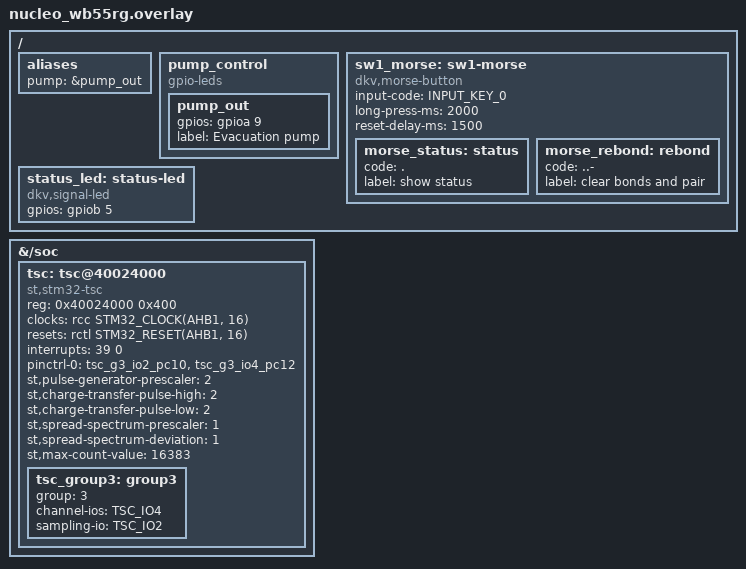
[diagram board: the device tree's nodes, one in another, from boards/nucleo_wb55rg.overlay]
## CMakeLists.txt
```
cmake_minimum_required(VERSION 3.20.0)

# Board-specific overlay/conf are auto-picked from boards/<board>.{overlay,conf}
set(BOARD_ROOT ${CMAKE_CURRENT_LIST_DIR})

# Default target board. Override on the command line with:
#   west build -b <board> .
if(NOT DEFINED BOARD)
  set(BOARD "nucleo_wb55rg")
endif()

# Use OpenOCD as the default flash/debug runner (the board otherwise defaults to
# stm32cubeprogrammer). `west flash` / `west debug` now use OpenOCD with no -r.
if(NOT DEFINED BOARD_FLASH_RUNNER)
  set(BOARD_FLASH_RUNNER openocd)
endif()
if(NOT DEFINED BOARD_DEBUG_RUNNER)
  set(BOARD_DEBUG_RUNNER openocd)
endif()

# Out-of-tree drivers (morse-button, signal-led) live in a Zephyr module.
list(APPEND ZEPHYR_EXTRA_MODULES ${CMAKE_CURRENT_LIST_DIR}/drivers)

find_package(Zephyr REQUIRED HINTS $ENV{ZEPHYR_BASE})
project(bucket C)

target_sources(app PRIVATE
  src/main.c
  src/pump.c
  src/level.c
  src/tsc.c
  src/gatt.c
  src/bond.c
  src/ui.c
)
```

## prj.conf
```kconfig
# ---- bucket firmware base config ----

CONFIG_MAIN_STACK_SIZE=2048

# Logging over the USB VCP / RTT. Cheap during bring-up; trim later for power.
CONFIG_LOG=y
CONFIG_SERIAL=y
CONFIG_CONSOLE=y
CONFIG_UART_CONSOLE=y

# Interactive shell over the ST-LINK virtual COM port (milestone-1 bring-up).
CONFIG_SHELL=y
CONFIG_SHELL_BACKEND_SERIAL=y
CONFIG_LOG_BACKEND_UART=y
CONFIG_KERNEL_SHELL=y
CONFIG_DEVICE_SHELL=y

# GPIO for the pump driver and status LED.
CONFIG_GPIO=y

# TSC capacitive sensing is exposed through the input subsystem.
# (The STM32 TSC driver is enabled by the devicetree overlay; it selects
#  CONFIG_INPUT automatically, but we ask for it explicitly for clarity.)
CONFIG_INPUT=y

# ---- Bluetooth LE (STM32WB) ----
CONFIG_BT=y
CONFIG_BT_PERIPHERAL=y
CONFIG_BT_DEVICE_NAME="BucketEvac"
CONFIG_BT_DIS=y
CONFIG_BT_DIS_MODEL_NUMBER=y
CONFIG_BT_DIS_MODEL_NUMBER_STR="BucketEvac"
CONFIG_BT_DIS_MANUF_NAME=y
CONFIG_BT_DIS_MANUF_NAME_STR="Denis Kokarev"
# BT shell commands for bring-up experimentation.
CONFIG_BT_SHELL=y

# ---- Pairing / bonding ----
# Secure (encrypted) GATT access with persistent bonds. New pairings are only
# accepted during a bonding window (see src/bond.c), gated via the
# pairing-accept callback.
CONFIG_BT_SMP=y
CONFIG_BT_BONDABLE=y
CONFIG_BT_SMP_APP_PAIRING_ACCEPT=y

# Persist bonds in the `storage` flash partition.
CONFIG_BT_SETTINGS=y
CONFIG_FLASH=y
CONFIG_FLASH_MAP=y
CONFIG_NVS=y
CONFIG_SETTINGS=y
# `settings list|read|write|delete` to inspect/wipe stored bonds (bt/keys/...).
CONFIG_SETTINGS_SHELL=y
CONFIG_SHELL_STACK_SIZE=4096
# e2e cleanup: `flash erase` the storage partition, then `kernel reboot cold`.
CONFIG_FLASH_SHELL=y
CONFIG_REBOOT=y
# `input report` injects SW1 presses (e2e drives the morse codes with it).
CONFIG_INPUT_SHELL=y

# Kernel niceties
CONFIG_PRINTK=y
CONFIG_CBPRINTF_FP_SUPPORT=y

# The BT host's deferred settings store (bonds + CCCs -> NVS) runs on the
# system workqueue; 1 KiB overflowed when a bond with two CCCs was re-paired.
CONFIG_SYSTEM_WORKQUEUE_STACK_SIZE=2048
```

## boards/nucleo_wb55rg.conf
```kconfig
# Board-specific Kconfig fragment for nucleo_wb55rg.
# Auto-merged with prj.conf when BOARD=nucleo_wb55rg.

# The WB55 BLE stack runs on the Cortex-M0+ radio coprocessor; the HCI link to
# it is provided by the IPM/IPC transport. Keep BT managed here so a non-BLE
# board build (e.g. for host tests) stays clean.
CONFIG_BT=y
```

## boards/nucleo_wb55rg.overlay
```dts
/*
 * nucleo_wb55rg overlay for the bucket project.
 *
 * Two jobs:
 *   1. Instantiate the STM32WB55 TSC peripheral. Unlike the F0/U0 SoCs, the
 *      WB `.dtsi` does NOT ship a `tsc` node, so we add it here. Register
 *      address / IRQ / clock / reset come from the STM32WB55 reference manual
 *      and CMSIS headers:
 *        TSC @ 0x40024000, IRQ 39, RCC AHB1 bit 16 (TSCEN/TSCRST).
 *   2. Declare the `pump` GPIO output.
 *   3. Board UI: SW1 as a morse button (codes below) and LED1 (blue, PB5)
 *      as the signal LED. PB5 has no timer PWM output on the WB55, so the
 *      signal-led driver uses software PWM on the GPIO.
 *
 * TSC pin choice: Group 3, on the ARDUINO headers (UM2819 Table 9), with no
 * other board function on either pin:
 *   - PC10 = G3_IO2 = D4 (CN9-5) -> sampling capacitor (external Cs to GND)
 *   - PC12 = G3_IO4 = D8 (CN5-1) -> sensing electrode (via series Rs)
 * G3_IO1 (PA15/D5) is avoided: the board DTS binds it to pwm2. Group 1
 * (PB12-15) is morpho-only and PB12 is the board's LPUART1 RTS.
 * Keep sampling-io and channel-ios in the same group.
 */

#include <zephyr/dt-bindings/input/input-event-codes.h>
#include <zephyr/dt-bindings/input/stm32-tsc-defines.h>

/ {
	aliases {
		pump = &pump_out;
	};

	/* Simple GPIO output for the pump driver transistor (base resistor):
	 * PA9 = ARDUINO D9 (CN5-2), high = pump ON. D10-D13 (PA4-PA7) are
	 * avoided: the board DTS gives them to spi1 (PA6 also LPUART1 CTS). */
	pump_control {
		compatible = "gpio-leds";
		pump_out: pump_out {
			gpios = <&gpioa 9 GPIO_ACTIVE_HIGH>;
			label = "Evacuation pump";
		};
	};

	/* SW1 (gpio-keys INPUT_KEY_0) decoded as morse codes. No `input`
	 * phandle: listen to any device so `input report` can inject presses
	 * from the shell (e2e). */
	sw1_morse: sw1-morse {
		compatible = "dkv,morse-button";
		input-code = <INPUT_KEY_0>;
		long-press-ms = <2000>;
		reset-delay-ms = <1500>;

		morse_status: status {
			code = ".";
			label = "show status";
		};
		morse_rebond: rebond {
			code = "..-";
			label = "clear bonds and pair";
		};
	};

	status_led: status-led {
		compatible = "dkv,signal-led";
		gpios = <&gpiob 5 GPIO_ACTIVE_HIGH>;
	};
};

/* The WB `soc` node is unlabeled; extend it by path to add the TSC. */
&{/soc} {
	tsc: tsc@40024000 {
		compatible = "st,stm32-tsc";
		reg = <0x40024000 0x400>;
		clocks = <&rcc STM32_CLOCK(AHB1, 16)>;
		resets = <&rctl STM32_RESET(AHB1, 16)>;
		interrupts = <39 0>;
		interrupt-names = "global";

		pinctrl-0 = <&tsc_g3_io2_pc10 &tsc_g3_io4_pc12>;
		pinctrl-names = "default";

		st,pulse-generator-prescaler = <2>;
		st,charge-transfer-pulse-high = <2>;
		st,charge-transfer-pulse-low = <2>;
		st,spread-spectrum-prescaler = <1>;
		st,spread-spectrum-deviation = <1>;
		st,max-count-value = <16383>;

		status = "okay";

		tsc_group3: group3 {
			/* Hardware TSC Group 3. The driver indexes registers as
			 * (group - 1), so Group 3 is `group = <3>`. */
			group = <3>;
			channel-ios = <TSC_IO4>;  /* PC12 / D8 electrode */
			sampling-io = <TSC_IO2>;  /* PC10 / D4 + external Cs */
			/* No `tsc-keys` child: we read the raw acquisition count
			 * ourselves (see src/tsc.c) for level sensing + validation. */
		};
	};
};
```

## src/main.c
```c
/*
 * bucket — dehumidifier bucket auto-evacuator
 *
 * Milestone 1 bring-up: boot the WB55, initialize the TSC capacitive sensor
 * and the Bluetooth controller, and run a shell. The pump control loop is
 * wired in but harmless until a real electrode + pump are connected and the
 * TSC thresholds are characterized.
 */
#include "adv.h"
#include "bond.h"
#include "gatt.h"
#include "level.h"
#include "pump.h"
#include "ui.h"

#include <zephyr/bluetooth/bluetooth.h>
#include <zephyr/bluetooth/conn.h>
#include <zephyr/bluetooth/uuid.h>
#include <zephyr/kernel.h>
#include <zephyr/logging/log.h>
#include <zephyr/settings/settings.h>

LOG_MODULE_REGISTER(main, LOG_LEVEL_INF);

#define CONTROL_PERIOD_MS 200

/* Service UUID in the primary advertisement so centrals can filter/scan for us;
 * must match gatt.c / client ble.ts. Name + bonding marker go in the scan
 * response (name + UUID together would overflow a single 31-byte packet). */
static const struct bt_data ad[] = {
	BT_DATA_BYTES(BT_DATA_FLAGS, (BT_LE_AD_GENERAL | BT_LE_AD_NO_BREDR)),
	BT_DATA_BYTES(BT_DATA_UUID128_ALL,
		      BT_UUID_128_ENCODE(0xd2f2a658, 0x2605, 0x4993, 0x9794, 0x01961b93a091)),
};

/* Manufacturer data: company 0xFFFF (test/internal) + a bonding-mode flag byte.
 * mfg_data[2] == 1 while the bonding window is open (see bt_set_bonding_adv). */
static uint8_t mfg_data[] = {0xFF, 0xFF, 0x00};

static const struct bt_data sd[] = {
	BT_DATA(BT_DATA_NAME_COMPLETE, CONFIG_BT_DEVICE_NAME, sizeof(CONFIG_BT_DEVICE_NAME) - 1),
	BT_DATA(BT_DATA_MANUFACTURER_DATA, mfg_data, sizeof(mfg_data)),
};

void bt_set_bonding_adv(bool on)
{
	mfg_data[2] = on ? 1 : 0;
	/* Live-update if currently advertising; the byte is also authoritative for
	 * the next start_adv(), so ignore errors (e.g. while connected). */
	(void)bt_le_adv_update_data(ad, ARRAY_SIZE(ad), sd, ARRAY_SIZE(sd));
}

static int start_adv(void)
{
	int err = bt_le_adv_start(BT_LE_ADV_CONN_FAST_1, ad, ARRAY_SIZE(ad), sd, ARRAY_SIZE(sd));
	if (err == 0) {
		LOG_INF("advertising as \"%s\"", CONFIG_BT_DEVICE_NAME);
	}
	return err;
}

/*
 * Re-advertising is deferred to the system workqueue: restarting from inside
 * the disconnected callback fails with -ENOMEM on the WB controller because the
 * connection object isn't freed yet. Retry until a slot is available.
 */
static void adv_work_handler(struct k_work *work)
{
	int err = start_adv();
	if (err == -ENOMEM || err == -EAGAIN) {
		k_work_reschedule(k_work_delayable_from_work(work), K_MSEC(100));
	} else if (err) {
		LOG_ERR("advertising start failed (%d)", err);
	}
}

static K_WORK_DELAYABLE_DEFINE(adv_work, adv_work_handler);

static void on_connected(struct bt_conn *conn, uint8_t err)
{
	char addr[BT_ADDR_LE_STR_LEN];

	if (err) {
		LOG_ERR("connection failed (0x%02x)", err);
		return;
	}
	bt_addr_le_to_str(bt_conn_get_dst(conn), addr, sizeof(addr));
	LOG_INF("central connected: %s (sec L%d)", addr, bt_conn_get_security(conn));
}

static void on_disconnected(struct bt_conn *conn, uint8_t reason)
{
	/* Connectable advertising stops on connect; restart it (deferred) so the
	 * board is discoverable again after the central goes away. */
	LOG_INF("central disconnected (reason 0x%02x), re-advertising", reason);
	k_work_reschedule(&adv_work, K_MSEC(50));
}

static void on_security_changed(struct bt_conn *conn, bt_security_t level,
				enum bt_security_err err)
{
	char addr[BT_ADDR_LE_STR_LEN];

	bt_addr_le_to_str(bt_conn_get_dst(conn), addr, sizeof(addr));
	if (err) {
		LOG_WRN("security change failed: %s L%d err %d", addr, level, err);
	} else {
		LOG_INF("security changed: %s L%d", addr, level);
	}
}

BT_CONN_CB_DEFINE(conn_cbs) = {
	.connected = on_connected,
	.disconnected = on_disconnected,
	.security_changed = on_security_changed,
};

static void bt_bringup(void)
{
	int err = bt_enable(NULL);
	if (err) {
		LOG_ERR("bt_enable failed (%d) — is the WB55 wireless coprocessor "
			"stack flashed on the M0+?",
			err);
		return;
	}
	LOG_INF("Bluetooth controller ready");

	if (IS_ENABLED(CONFIG_SETTINGS)) {
		settings_load(); /* restore stored bonds */
	}
	if (bond_init(ui_on_bond_event) != 0) {
		LOG_ERR("bond init failed");
	}
	if (ui_init() != 0) {
		LOG_ERR("ui init failed");
	}
	ui_show_status();

	if (start_adv() != 0) {
		k_work_reschedule(&adv_work, K_MSEC(100));
	}
}

int main(void)
{
	LOG_INF("bucket starting on %s", CONFIG_BOARD);

	if (pump_init() != 0) {
		LOG_ERR("pump init failed");
	}
	if (level_init() != 0) {
		LOG_ERR("level init failed");
	}

	bt_bringup();

	LOG_INF("bring-up complete: TSC + BT + shell running");

	/* Control loop: in AUTO follow the level sensor; FORCE_ON/OFF come from
	 * the BLE pump characteristic. The min-run / max-run guards are enforced
	 * inside the pump module. Status is pushed to subscribed centrals. */
	while (1) {
		switch (pump_get_mode()) {
		case PUMP_MODE_FORCE_ON:
			pump_request(true);
			break;
		case PUMP_MODE_FORCE_OFF:
			pump_request(false);
			break;
		case PUMP_MODE_AUTO:
		default:
			pump_request(level_water_present());
			break;
		}
		pump_tick();
		bucket_gatt_notify();
		k_sleep(K_MSEC(CONTROL_PERIOD_MS));
	}

	return 0;
}
```

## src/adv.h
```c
/*
 * Advertising control shared between main.c (owns the advertiser) and bond.c
 * (opens/closes the bonding window).
 */
#ifndef BUCKET_ADV_H
#define BUCKET_ADV_H

#include <stdbool.h>

/*
 * Toggle the "bonding mode" marker in the advertising data. The mobile client
 * only auto-pairs when it sees this marker, so pairing is effectively initiated
 * by the user opening the window (SW1 / `bond`), not by mere discovery.
 */
void bt_set_bonding_adv(bool on);

#endif /* BUCKET_ADV_H */
```

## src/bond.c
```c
#include "bond.h"
#include "adv.h"

#include <string.h>
#include <zephyr/bluetooth/bluetooth.h>
#include <zephyr/bluetooth/conn.h>
#include <zephyr/kernel.h>
#include <zephyr/logging/log.h>
#include <zephyr/shell/shell.h>
#include <zephyr/sys/atomic.h>

LOG_MODULE_REGISTER(bond, LOG_LEVEL_INF);

#define BOND_WINDOW_SECONDS 60

static atomic_t window_open; /* 1 while new pairings are accepted */
static bond_event_cb_t event_cb;

static void notify(enum bond_event ev)
{
	if (event_cb) {
		event_cb(ev);
	}
}

/* Close the window if it is open; true if this call closed it. Callers race
 * (timeout vs. pairing result), so exactly one of them reports. */
static bool close_window(void)
{
	if (!atomic_cas(&window_open, 1, 0)) {
		return false;
	}
	bt_set_bonding_adv(false);
	return true;
}

/* Runs in the system workqueue (thread context) so BT APIs are safe. */
static void window_timeout(struct k_work *work)
{
	ARG_UNUSED(work);
	if (close_window()) {
		LOG_INF("bonding window closed (timeout)");
		notify(BOND_EV_WINDOW_TIMEOUT);
	}
}

static K_WORK_DELAYABLE_DEFINE(window_work, window_timeout);

static void count_bond(const struct bt_bond_info *info, void *user_data)
{
	ARG_UNUSED(info);
	(*(int *)user_data)++;
}

bool bond_exists(void)
{
	int n = 0;

	bt_foreach_bond(BT_ID_DEFAULT, count_bond, &n);
	return n > 0;
}

bool bond_window_is_open(void)
{
	return atomic_get(&window_open) != 0;
}

void bond_rebond(void)
{
	/* Clear first so the board always re-pairs from scratch: a phone that
	 * dropped its keys (OS-side unpair) can pair again, and the window only
	 * ever ends with exactly the newly paired phone bonded. Connected peers
	 * are disconnected by bt_unpair(). */
	int err = bt_unpair(BT_ID_DEFAULT, NULL);

	LOG_INF("cleared all bonds (%d)", err);
	atomic_set(&window_open, 1);
	bt_set_bonding_adv(true); /* advertise the marker so the app auto-pairs */
	k_work_reschedule(&window_work, K_SECONDS(BOND_WINDOW_SECONDS));
	LOG_INF("bonding mode: accepting a new pairing for %d s "
		"(read the secure Pump attribute from the client)",
		BOND_WINDOW_SECONDS);
	notify(BOND_EV_WINDOW_OPEN);
}

/* ---- pairing callbacks ---- */

#if defined(CONFIG_BT_SMP_APP_PAIRING_ACCEPT)
static enum bt_security_err pairing_accept(struct bt_conn *conn,
					   const struct bt_conn_pairing_feat *const feat)
{
	ARG_UNUSED(conn);
	ARG_UNUSED(feat);

	if (atomic_get(&window_open)) {
		LOG_INF("pairing request accepted");
		return BT_SECURITY_ERR_SUCCESS;
	}

	LOG_WRN("pairing rejected: not in bonding mode (SW1 short-short-long or `bond`)");
	return BT_SECURITY_ERR_PAIR_NOT_ALLOWED;
}
#endif

static const struct bt_conn_auth_cb auth_cb = {
#if defined(CONFIG_BT_SMP_APP_PAIRING_ACCEPT)
	.pairing_accept = pairing_accept,
#endif
};

static void pairing_complete(struct bt_conn *conn, bool bonded)
{
	char addr[BT_ADDR_LE_STR_LEN];

	bt_addr_le_to_str(bt_conn_get_dst(conn), addr, sizeof(addr));
	LOG_INF("pairing complete: %s (bonded=%d)", addr, bonded);
	/* One successful bond per window. */
	if (close_window()) {
		k_work_cancel_delayable(&window_work);
		notify(BOND_EV_PAIRED);
	}
}

static void pairing_failed(struct bt_conn *conn, enum bt_security_err reason)
{
	ARG_UNUSED(conn);
	LOG_WRN("pairing failed (reason %d)", reason);
	/* Only a failure inside the window is the user's pairing attempt; outside
	 * it, it's a rejected stranger and must not change the UI. */
	if (close_window()) {
		k_work_cancel_delayable(&window_work);
		notify(BOND_EV_FAILED);
	}
}

static struct bt_conn_auth_info_cb auth_info_cb = {
	.pairing_complete = pairing_complete,
	.pairing_failed = pairing_failed,
};

int bond_init(bond_event_cb_t cb)
{
	int err;

	event_cb = cb;
	err = bt_conn_auth_cb_register(&auth_cb);
	if (err) {
		return err;
	}
	return bt_conn_auth_info_cb_register(&auth_info_cb);
}

/* ---- shell ---- */

static int cmd_bond(const struct shell *sh, size_t argc, char **argv)
{
	if (argc > 1 && strcmp(argv[1], "clear") == 0) {
		int err = bt_unpair(BT_ID_DEFAULT, NULL); /* remove all bonds (recovery) */
		shell_print(sh, "cleared all bonds (%d)", err);
		return 0;
	}
	bond_rebond();
	shell_print(sh, "bonding mode ON for %d s — read the secure Pump attribute to pair",
		    BOND_WINDOW_SECONDS);
	return 0;
}

SHELL_CMD_REGISTER(bond, NULL,
		   "Clear bonds and open the bonding window for 60s (same as SW1 "
		   "short-short-long); `bond clear` only drops all bonds",
		   cmd_bond);
```

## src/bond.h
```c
/*
 * BLE bonding control.
 *
 * New pairings are only accepted during a short "bonding window". It is opened
 * by bond_rebond() (SW1 code short-short-long, or the `bond` shell command),
 * which first clears all existing bonds, so the board is always re-paired from
 * scratch. A client pairs during that window by reading the secure Pump
 * characteristic. Already-bonded centrals reconnect with their stored keys at
 * any time, without the window.
 */
#ifndef BUCKET_BOND_H
#define BUCKET_BOND_H

#include <stdbool.h>

enum bond_event {
	BOND_EV_WINDOW_OPEN,    /* bonds cleared, accepting a new pairing */
	BOND_EV_PAIRED,         /* a new bond was stored; window closed */
	BOND_EV_WINDOW_TIMEOUT, /* window expired without a pairing */
	BOND_EV_FAILED,         /* pairing failed during the window; window closed */
};

typedef void (*bond_event_cb_t)(enum bond_event ev);

/* Register pairing callbacks; @p cb (may be NULL) gets bond events. Call after
 * bt_enable() and settings_load(). Returns 0 on success. */
int bond_init(bond_event_cb_t cb);

/* Clear all bonds, then open the bonding window for BOND_WINDOW_SECONDS. */
void bond_rebond(void);

bool bond_exists(void);
bool bond_window_is_open(void);

#endif /* BUCKET_BOND_H */
```

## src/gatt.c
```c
#include "gatt.h"
#include "level.h"
#include "pump.h"
#include "tsc.h"

#include <zephyr/bluetooth/gatt.h>
#include <zephyr/bluetooth/uuid.h>
#include <zephyr/kernel.h>
#include <zephyr/logging/log.h>
#include <zephyr/sys/byteorder.h>

LOG_MODULE_REGISTER(gatt, LOG_LEVEL_INF);

/* Service + characteristic UUIDs (must match client/src/utils/ble.ts). */
#define BUCKET_SVC_UUID    BT_UUID_128_ENCODE(0xd2f2a658, 0x2605, 0x4993, 0x9794, 0x01961b93a091)
#define BUCKET_LEVEL_UUID  BT_UUID_128_ENCODE(0x3ec2dc2f, 0xcfdf, 0x49e1, 0xb232, 0xda0dc4a88003)
#define BUCKET_PUMP_UUID   BT_UUID_128_ENCODE(0x4feebce2, 0xe1af, 0x4634, 0x915d, 0x9e62b0756af1)
#define BUCKET_THR_UUID    BT_UUID_128_ENCODE(0xabbb42ed, 0xde11, 0x4636, 0xbbfa, 0x09158f1b0177)

static const struct bt_uuid_128 svc_uuid = BT_UUID_INIT_128(BUCKET_SVC_UUID);
static const struct bt_uuid_128 level_uuid = BT_UUID_INIT_128(BUCKET_LEVEL_UUID);
static const struct bt_uuid_128 pump_uuid = BT_UUID_INIT_128(BUCKET_PUMP_UUID);
static const struct bt_uuid_128 thr_uuid = BT_UUID_INIT_128(BUCKET_THR_UUID);

static bool level_notify_enabled;
static bool thr_notify_enabled;

/* Level payload: [water:u8, pump:u8, rawTSC:u16 LE]. */
static void fill_level(uint8_t buf[4])
{
	uint32_t count = tsc_last_count();
	uint16_t raw = count > UINT16_MAX ? UINT16_MAX : (uint16_t)count;

	buf[0] = level_water_present() ? 1 : 0;
	buf[1] = pump_is_on() ? 1 : 0;
	buf[2] = (uint8_t)(raw & 0xff);
	buf[3] = (uint8_t)(raw >> 8);
}

static ssize_t read_level(struct bt_conn *conn, const struct bt_gatt_attr *attr, void *buf,
			  uint16_t len, uint16_t offset)
{
	uint8_t value[4];

	fill_level(value);
	return bt_gatt_attr_read(conn, attr, buf, len, offset, value, sizeof(value));
}

static void level_ccc_changed(const struct bt_gatt_attr *attr, uint16_t value)
{
	level_notify_enabled = (value == BT_GATT_CCC_NOTIFY);
	LOG_INF("level notifications %s", level_notify_enabled ? "enabled" : "disabled");
}

static ssize_t read_pump(struct bt_conn *conn, const struct bt_gatt_attr *attr, void *buf,
			 uint16_t len, uint16_t offset)
{
	uint8_t mode = (uint8_t)pump_get_mode();

	return bt_gatt_attr_read(conn, attr, buf, len, offset, &mode, sizeof(mode));
}

static ssize_t write_pump(struct bt_conn *conn, const struct bt_gatt_attr *attr, const void *buf,
			  uint16_t len, uint16_t offset, uint8_t flags)
{
	if (offset != 0 || len != 1) {
		return BT_GATT_ERR(BT_ATT_ERR_INVALID_ATTRIBUTE_LEN);
	}

	uint8_t v = ((const uint8_t *)buf)[0];
	if (v > PUMP_MODE_FORCE_ON) {
		return BT_GATT_ERR(BT_ATT_ERR_VALUE_NOT_ALLOWED);
	}

	pump_set_mode((enum pump_mode)v);
	return len;
}

/* Thresholds payload: [off:u16 LE, on:u16 LE] (pump OFF above, ON below). */
static void fill_thresholds(uint8_t buf[4])
{
	uint16_t off, on;

	level_get_thresholds(&off, &on);
	sys_put_le16(off, &buf[0]);
	sys_put_le16(on, &buf[2]);
}

static ssize_t read_thr(struct bt_conn *conn, const struct bt_gatt_attr *attr, void *buf,
			uint16_t len, uint16_t offset)
{
	uint8_t value[4];

	fill_thresholds(value);
	return bt_gatt_attr_read(conn, attr, buf, len, offset, value, sizeof(value));
}

static ssize_t write_thr(struct bt_conn *conn, const struct bt_gatt_attr *attr, const void *buf,
			 uint16_t len, uint16_t offset, uint8_t flags)
{
	if (offset != 0 || len != 4) {
		return BT_GATT_ERR(BT_ATT_ERR_INVALID_ATTRIBUTE_LEN);
	}

	const uint8_t *v = buf;

	if (level_set_thresholds(sys_get_le16(&v[0]), sys_get_le16(&v[2])) != 0) {
		return BT_GATT_ERR(BT_ATT_ERR_VALUE_NOT_ALLOWED);
	}
	return len;
}

static void thr_ccc_changed(const struct bt_gatt_attr *attr, uint16_t value)
{
	thr_notify_enabled = (value == BT_GATT_CCC_NOTIFY);
	LOG_INF("threshold notifications %s", thr_notify_enabled ? "enabled" : "disabled");
}

/* clang-format off */
BT_GATT_SERVICE_DEFINE(bucket_svc,
	BT_GATT_PRIMARY_SERVICE(&svc_uuid),
	BT_GATT_CHARACTERISTIC(&level_uuid.uuid,
			       BT_GATT_CHRC_READ | BT_GATT_CHRC_NOTIFY,
			       BT_GATT_PERM_READ,
			       read_level, NULL, NULL),
	BT_GATT_CCC(level_ccc_changed, BT_GATT_PERM_READ | BT_GATT_PERM_WRITE),
	/* Pump is secure: read + write require an encrypted (bonded) link. A
	 * client reads this attribute to trigger pairing during the bonding
	 * window (see src/bond.c). */
	BT_GATT_CHARACTERISTIC(&pump_uuid.uuid,
			       BT_GATT_CHRC_READ | BT_GATT_CHRC_WRITE,
			       BT_GATT_PERM_READ_ENCRYPT | BT_GATT_PERM_WRITE_ENCRYPT,
			       read_pump, write_pump, NULL),
	/* Pump thresholds (persistent settings): encrypted read/write/subscribe. */
	BT_GATT_CHARACTERISTIC(&thr_uuid.uuid,
			       BT_GATT_CHRC_READ | BT_GATT_CHRC_WRITE | BT_GATT_CHRC_NOTIFY,
			       BT_GATT_PERM_READ_ENCRYPT | BT_GATT_PERM_WRITE_ENCRYPT,
			       read_thr, write_thr, NULL),
	BT_GATT_CCC(thr_ccc_changed, BT_GATT_PERM_READ | BT_GATT_PERM_WRITE_ENCRYPT),
);
/* clang-format on */

void bucket_gatt_notify(void)
{
	if (!level_notify_enabled) {
		return;
	}

	uint8_t value[4];

	fill_level(value);
	/* attrs[1] is the Level characteristic value attribute. */
	bt_gatt_notify(NULL, &bucket_svc.attrs[1], value, sizeof(value));
}

void bucket_gatt_thresholds_changed(void)
{
	if (!thr_notify_enabled) {
		return;
	}

	uint8_t value[4];

	fill_thresholds(value);
	/* attrs[6] is the Thresholds characteristic declaration. */
	bt_gatt_notify(NULL, &bucket_svc.attrs[6], value, sizeof(value));
}
```

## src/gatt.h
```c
/*
 * Bucket custom GATT service.
 *
 * Exposes the water-level status (read + notify) and the pump mode
 * (read + write) to a BLE central (the mobile client). UUIDs and payload
 * layouts are the contract shared with client/src/utils/ble.ts.
 */
#ifndef BUCKET_GATT_H
#define BUCKET_GATT_H

/*
 * Push the current level/pump status to any subscribed central.
 * Safe to call periodically; a no-op when nobody is subscribed.
 */
void bucket_gatt_notify(void);

/* Notify subscribed centrals of new pump thresholds (shell or GATT change). */
void bucket_gatt_thresholds_changed(void);

#endif /* BUCKET_GATT_H */
```

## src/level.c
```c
#include "level.h"
#include "tsc.h"

#include <zephyr/kernel.h>
#include <zephyr/logging/log.h>

LOG_MODULE_REGISTER(level, LOG_LEVEL_INF);

/*
 * Water raises the electrode capacitance, which LOWERS the TSC count. So water
 * is "present" when the count falls below LEVEL_TRIGGER_COUNT, and clears when
 * it rises back above LEVEL_RELEASE_COUNT (hysteresis to stop chatter).
 *
 * Calibrated for Cs = 10 nF and ~21 pF of pin/lead parasitic (bench, see
 * hard/tsc-validation.md). Electrode dry (2 pF) ~330, half band (18 pF) ~195,
 * full (34 pF) ~138. Trigger ~= 14 pF of water signal, release ~= 8 pF. If the
 * parasitic grows by more than ~8 pF, dry drops under the release level:
 * re-measure and re-set these (or move to baseline tracking).
 */
#define LEVEL_TRIGGER_COUNT 220
#define LEVEL_RELEASE_COUNT 260

/* Below this, no sampling cap / electrode is connected (the acquisition
 * completes in ~1 cycle) — not a real reading, so don't report "full". */
#define LEVEL_COUNT_MIN_VALID 20

static bool water_present;

int level_init(void)
{
	water_present = false;
	return tsc_init();
}

bool level_water_present(void)
{
	uint32_t count = tsc_last_count();

	if (count < LEVEL_COUNT_MIN_VALID) {
		/* No acquisition yet, or no electrode/sampling cap wired. */
		if (water_present) {
			water_present = false;
			LOG_INF("sensor not ready (count %u) -> dry", count);
		}
		return false;
	}

	if (water_present) {
		if (count > LEVEL_RELEASE_COUNT) {
			water_present = false;
			LOG_INF("water absent (count %u)", count);
		}
	} else {
		if (count < LEVEL_TRIGGER_COUNT) {
			water_present = true;
			LOG_INF("water PRESENT (count %u)", count);
		}
	}

	return water_present;
}
```

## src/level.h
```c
/*
 * Capacitive water-level sensing via the STM32 TSC.
 *
 * Reads the raw TSC acquisition count (see tsc.c) and applies a threshold with
 * hysteresis to expose a debounced "water present" state. Water raises the
 * electrode capacitance, which lowers the count.
 */
#ifndef BUCKET_LEVEL_H
#define BUCKET_LEVEL_H

#include <stdbool.h>
#include <stdint.h>

/* Set up the input-event subscription. Returns 0 on success. */
int level_init(void);

/* True once water has been detected at/above the electrode (trigger level). */
bool level_water_present(void);

/* Pump hysteresis in raw TSC counts: OFF above `off`, ON below `on`. */
void level_get_thresholds(uint16_t *off, uint16_t *on);

/* Validate (off > on), apply, persist and notify. -EINVAL if invalid. */
int level_set_thresholds(uint16_t off, uint16_t on);

#endif /* BUCKET_LEVEL_H */
```

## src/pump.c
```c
#include "pump.h"

#include <zephyr/device.h>
#include <zephyr/drivers/gpio.h>
#include <zephyr/kernel.h>
#include <zephyr/logging/log.h>

LOG_MODULE_REGISTER(pump, LOG_LEVEL_INF);

/* Minimum time the pump stays on once started, and minimum off time. */
#define PUMP_MIN_RUN_MS 3000
#define PUMP_MIN_OFF_MS 1000

/* Hard safety cap: never run the pump longer than this in one shot. */
#define PUMP_MAX_RUN_MS 120000

/* `pump` is a GPIO alias in boards/<board>.overlay. */
#define PUMP_NODE DT_ALIAS(pump)

#if DT_NODE_HAS_STATUS(PUMP_NODE, okay)
static const struct gpio_dt_spec pump_gpio = GPIO_DT_SPEC_GET(PUMP_NODE, gpios);
#define PUMP_HAVE_GPIO 1
#else
#define PUMP_HAVE_GPIO 0
#warning "no `pump` GPIO alias in devicetree; pump control is a no-op (bring-up stub)"
#endif

static bool state_on;           /* actual output state */
static bool want_on;            /* last requested state */
static int64_t last_change_ms;  /* uptime at last actual transition */
static enum pump_mode mode = PUMP_MODE_AUTO;

static void apply(bool on)
{
	if (on == state_on) {
		return;
	}
#if PUMP_HAVE_GPIO
	gpio_pin_set_dt(&pump_gpio, on ? 1 : 0);
#endif
	state_on = on;
	last_change_ms = k_uptime_get();
	LOG_INF("pump %s", on ? "ON" : "OFF");
}

int pump_init(void)
{
	state_on = false;
	want_on = false;
	last_change_ms = k_uptime_get();

#if PUMP_HAVE_GPIO
	if (!gpio_is_ready_dt(&pump_gpio)) {
		LOG_ERR("pump GPIO not ready");
		return -ENODEV;
	}
	int ret = gpio_pin_configure_dt(&pump_gpio, GPIO_OUTPUT_INACTIVE);
	if (ret < 0) {
		LOG_ERR("pump GPIO config failed (%d)", ret);
		return ret;
	}
#else
	LOG_WRN("pump GPIO not defined; running as a no-op stub");
#endif
	return 0;
}

void pump_set_mode(enum pump_mode m)
{
	if (m != mode) {
		mode = m;
		LOG_INF("pump mode -> %d", (int)m);
	}
}

enum pump_mode pump_get_mode(void)
{
	return mode;
}

void pump_request(bool on)
{
	want_on = on;
}

void pump_tick(void)
{
	int64_t now = k_uptime_get();
	int64_t held = now - last_change_ms;

	if (want_on && !state_on) {
		if (held >= PUMP_MIN_OFF_MS) {
			apply(true);
		}
	} else if (!want_on && state_on) {
		if (held >= PUMP_MIN_RUN_MS) {
			apply(false);
		}
	}

	/* Safety: force off if we've been running too long. */
	if (state_on && held >= PUMP_MAX_RUN_MS) {
		LOG_WRN("pump max run-time reached, forcing OFF");
		apply(false);
		want_on = false;
	}
}

bool pump_is_on(void)
{
	return state_on;
}
```

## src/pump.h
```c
/*
 * Evacuation pump actuation.
 *
 * Drives the `pump` GPIO (see devicetree overlay) through an external
 * MOSFET/relay, with a minimum run-time guard so the pump can't chatter when
 * the level sensor hovers around the trigger point.
 */
#ifndef BUCKET_PUMP_H
#define BUCKET_PUMP_H

#include <stdbool.h>
#include <stdint.h>

/*
 * Pump control mode (values match the BLE Pump characteristic and the mobile
 * client's PumpMode enum).
 */
enum pump_mode {
	PUMP_MODE_AUTO = 0,     /* follow the level sensor */
	PUMP_MODE_FORCE_OFF = 1, /* manual: keep the pump off */
	PUMP_MODE_FORCE_ON = 2,  /* manual: keep the pump on */
};

/* Initialize the pump GPIO (off). Returns 0 on success, <0 on error. */
int pump_init(void);

/* Set/get the control mode. Default is PUMP_MODE_AUTO. */
void pump_set_mode(enum pump_mode mode);
enum pump_mode pump_get_mode(void);

/*
 * Request the pump on/off. Honors a minimum run-time once started: a request
 * to stop before PUMP_MIN_RUN_MS has elapsed is deferred. Call pump_tick()
 * periodically so deferred transitions actually happen.
 */
void pump_request(bool on);

/* Service deferred transitions / safety timers. Call from the control loop. */
void pump_tick(void);

/* Current actual pump state. */
bool pump_is_on(void);

#endif /* BUCKET_PUMP_H */
```

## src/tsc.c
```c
#include "tsc.h"

#include <zephyr/device.h>
#include <zephyr/devicetree.h>
#include <zephyr/kernel.h>
#include <zephyr/logging/log.h>
#include <zephyr/shell/shell.h>

LOG_MODULE_REGISTER(tsc, LOG_LEVEL_INF);

/*
 * The st,stm32-tsc driver exports these but ships no public header, so we
 * declare the prototypes ourselves. (drivers/input/input_tsc_keys.c)
 */
typedef void (*stm32_tsc_group_ready_cb)(uint32_t count_value, void *user_data);
extern int stm32_tsc_group_register_callback(const struct device *dev, uint8_t group_idx,
					     stm32_tsc_group_ready_cb cb, void *user_data);
extern void stm32_tsc_start(const struct device *dev);

/* Our single configured group is index 0 in the driver's group array. */
#define TSC_GROUP_IDX 0
#define TSC_SAMPLE_PERIOD_MS 200

static const struct device *const tsc_dev = DEVICE_DT_GET(DT_NODELABEL(tsc));

static volatile uint32_t last_count;

static void group_ready(uint32_t count_value, void *user_data)
{
	ARG_UNUSED(user_data);
	last_count = count_value;
}

static void sample_timer_expiry(struct k_timer *timer)
{
	ARG_UNUSED(timer);
	/* Kick off the next acquisition; the result arrives via group_ready(). */
	stm32_tsc_start(tsc_dev);
}

static K_TIMER_DEFINE(sample_timer, sample_timer_expiry, NULL);

uint32_t tsc_last_count(void)
{
	return last_count;
}

int tsc_init(void)
{
	if (!device_is_ready(tsc_dev)) {
		LOG_ERR("TSC device not ready");
		return -ENODEV;
	}

	int ret = stm32_tsc_group_register_callback(tsc_dev, TSC_GROUP_IDX, group_ready, NULL);
	if (ret < 0) {
		LOG_ERR("TSC callback register failed (%d)", ret);
		return ret;
	}

	k_timer_start(&sample_timer, K_NO_WAIT, K_MSEC(TSC_SAMPLE_PERIOD_MS));
	LOG_INF("TSC sampling every %d ms (group 3)", TSC_SAMPLE_PERIOD_MS);
	return 0;
}

/* `tsc` shell command: print the latest raw count (for the bench sweep). */
static int cmd_tsc(const struct shell *sh, size_t argc, char **argv)
{
	ARG_UNUSED(argc);
	ARG_UNUSED(argv);
	shell_print(sh, "g3 count = %u", tsc_last_count());
	return 0;
}

SHELL_CMD_REGISTER(tsc, NULL, "Print the latest raw TSC acquisition count", cmd_tsc);
```

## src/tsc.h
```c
/*
 * Raw STM32 TSC acquisition for the water-level electrode.
 *
 * The Zephyr st,stm32-tsc driver exposes the raw per-group acquisition count
 * through a group-ready callback (there is no `tsc-keys` child here). This
 * module owns TSC Group 1, triggers periodic acquisitions, keeps the latest
 * count, and reports it (periodic log + `tsc` shell command) for the
 * characterization work in hard/tsc-validation.md.
 *
 * Recall: water raises the electrode capacitance Cx, which LOWERS the count
 * (count ≈ k·Cs/Cx).
 */
#ifndef BUCKET_TSC_H
#define BUCKET_TSC_H

#include <stdint.h>

/* Start periodic TSC acquisition. Returns 0 on success, <0 on error. */
int tsc_init(void);

/* Latest raw acquisition count for the electrode group (0 before first read). */
uint32_t tsc_last_count(void);

#endif /* BUCKET_TSC_H */
```

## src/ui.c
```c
#include "ui.h"

#include <drivers/morse_button.h>
#include <drivers/signal_led.h>
#include <zephyr/device.h>
#include <zephyr/kernel.h>
#include <zephyr/logging/log.h>

LOG_MODULE_REGISTER(ui, LOG_LEVEL_INF);

#define SHOW_FOR       K_SECONDS(60)
#define BLINK_2HZ_MS   500
#define GLOW_PERIOD_MS 2000

#define STATUS_CODE DT_NODELABEL(morse_status)
#define REBOND_CODE DT_NODELABEL(morse_rebond)

static const struct device *const led = DEVICE_DT_GET(DT_NODELABEL(status_led));

/* Log lines "led: <state>" are part of the e2e contract (test_e2e/board.py). */
static void led_show(const char *state, enum signal_led_mode mode, uint32_t period_ms,
		     k_timeout_t duration)
{
	int err = signal_led_set(led, mode, period_ms, duration);

	if (err) {
		LOG_ERR("led: %s failed (%d)", state, err);
		return;
	}
	LOG_INF("led: %s", state);
}

void ui_show_status(void)
{
	if (bond_window_is_open()) {
		LOG_INF("led: pairing (unchanged)"); /* the glow already says it */
	} else if (bond_exists()) {
		led_show("bonded", SIGNAL_LED_SOLID, 0, SHOW_FOR);
	} else {
		led_show("no-bond", SIGNAL_LED_BLINK, BLINK_2HZ_MS, SHOW_FOR);
	}
}

void ui_on_bond_event(enum bond_event ev)
{
	switch (ev) {
	case BOND_EV_WINDOW_OPEN:
		/* Until the window ends; the closing event changes it. */
		led_show("pairing", SIGNAL_LED_GLOW, GLOW_PERIOD_MS, K_FOREVER);
		break;
	case BOND_EV_PAIRED:
		led_show("bonded", SIGNAL_LED_SOLID, 0, SHOW_FOR);
		break;
	case BOND_EV_WINDOW_TIMEOUT:
		led_show("off", SIGNAL_LED_OFF, 0, K_FOREVER);
		break;
	case BOND_EV_FAILED:
		led_show("error", SIGNAL_LED_BLINK, BLINK_2HZ_MS, SHOW_FOR);
		break;
	}
}

static void on_status_code(const struct device *dev, size_t entry, void *user_data)
{
	ARG_UNUSED(dev);
	ARG_UNUSED(entry);
	ARG_UNUSED(user_data);
	ui_show_status();
}

static void on_rebond_code(const struct device *dev, size_t entry, void *user_data)
{
	ARG_UNUSED(dev);
	ARG_UNUSED(entry);
	ARG_UNUSED(user_data);
	bond_rebond();
}

int ui_init(void)
{
	const struct device *sw1 = MORSE_BUTTON_DEV(STATUS_CODE);
	int err;

	if (!device_is_ready(led) || !device_is_ready(sw1)) {
		LOG_ERR("status LED or SW1 morse button not ready");
		return -ENODEV;
	}
	err = morse_button_set_handler(sw1, MORSE_BUTTON_ENTRY(STATUS_CODE), on_status_code, NULL);
	if (err) {
		return err;
	}
	return morse_button_set_handler(MORSE_BUTTON_DEV(REBOND_CODE),
					MORSE_BUTTON_ENTRY(REBOND_CODE), on_rebond_code, NULL);
}
```
